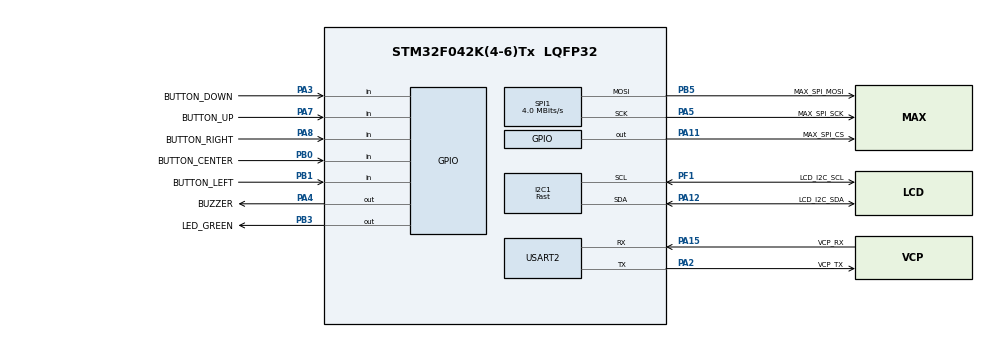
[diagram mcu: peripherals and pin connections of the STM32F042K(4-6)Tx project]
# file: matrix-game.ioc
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I2C1.I2C_Speed_Mode=I2C_Fast
I2C1.Timing=0x0010020A
Mcu.Family=STM32F0
Mcu.Name=STM32F042K(4-6)Tx
Mcu.Package=LQFP32
PA11.GPIO_Label=MAX_SPI_CS
PA11.PinState=GPIO_PIN_SET
PA11.Signal=GPIO_Output
PA12.GPIO_Label=LCD_I2C_SDA
PA12.Mode=I2C
PA12.Signal=I2C1_SDA
PA13.GPIO_Label=SWDIO
PA13.Mode=Serial_Wire
PA13.Signal=SYS_SWDIO
PA14.GPIO_Label=SWCLK
PA14.Mode=Serial_Wire
PA14.Signal=SYS_SWCLK
PA15.GPIO_Label=VCP_RX
PA15.Mode=Asynchronous
PA15.Signal=USART2_RX
PA2.GPIO_Label=VCP_TX
PA2.Mode=Asynchronous
PA2.Signal=USART2_TX
PA3.GPIO_Label=BUTTON_DOWN
PA3.GPIO_PuPd=GPIO_PULLDOWN
PA3.Signal=GPIO_Input
PA4.GPIO_Label=BUZZER
PA4.Signal=GPIO_Output
PA5.GPIO_Label=MAX_SPI_SCK
PA5.Mode=TX_Only_Simplex_Unidirect_Master
PA5.Signal=SPI1_SCK
PA7.GPIO_Label=BUTTON_UP
PA7.GPIO_PuPd=GPIO_PULLDOWN
PA7.Signal=GPIO_Input
PA8.GPIO_Label=BUTTON_RIGHT
PA8.GPIO_PuPd=GPIO_PULLDOWN
PA8.Signal=GPIO_Input
PB0.GPIO_Label=BUTTON_CENTER
PB0.GPIO_PuPd=GPIO_PULLDOWN
PB0.Signal=GPIO_Input
PB1.GPIO_Label=BUTTON_LEFT
PB1.GPIO_PuPd=GPIO_PULLDOWN
PB1.Signal=GPIO_Input
PB3.GPIO_Label=LED_GREEN
PB3.Signal=GPIO_Output
PB5.GPIO_Label=MAX_SPI_MOSI
PB5.Mode=TX_Only_Simplex_Unidirect_Master
PB5.Signal=SPI1_MOSI
PF0-OSC_IN.GPIO_Label=MCO
PF0-OSC_IN.Mode=HSE-External-Clock-Source
PF0-OSC_IN.Signal=RCC_OSC_IN
PF1-OSC_OUT.GPIO_Label=LCD_I2C_SCL
PF1-OSC_OUT.Mode=I2C
PF1-OSC_OUT.Signal=I2C1_SCL
ProjectManager.HeapSize=0x200
ProjectManager.StackSize=0x400
ProjectManager.TargetToolchain=STM32CubeIDE
SPI1.BaudRatePrescaler=SPI_BAUDRATEPRESCALER_2
SPI1.CalculateBaudRate=4.0 MBits/s
SPI1.DataSize=SPI_DATASIZE_16BIT
SPI1.Direction=SPI_DIRECTION_2LINES
SPI1.Mode=SPI_MODE_MASTER
SPI1.NSSPMode=SPI_NSS_PULSE_DISABLE
SPI1.VirtualType=VM_MASTER
USART2.VirtualMode-Asynchronous=VM_ASYNC
board=NUCLEO-F042K6

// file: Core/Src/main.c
/* USER CODE BEGIN Header */
/**
  ******************************************************************************
  * @file           : main.c
  * @brief          : Main program body
  ******************************************************************************
  * @attention
  *
  * Copyright (c) 2025 STMicroelectronics.
  * All rights reserved.
  *
  * This software is licensed under terms that can be found in the LICENSE file
  * in the root directory of this software component.
  * If no LICENSE file comes with this software, it is provided AS-IS.
  *
  ******************************************************************************
  */
/* USER CODE END Header */
#include "main.h"

/* USER CODE BEGIN Includes */
#include "app.h"

/* USER CODE END Includes */

I2C_HandleTypeDef hi2c1;

SPI_HandleTypeDef hspi1;

UART_HandleTypeDef huart2;

void SystemClock_Config(void);
static void MX_GPIO_Init(void);
static void MX_USART2_UART_Init(void);
static void MX_I2C1_Init(void);
static void MX_SPI1_Init(void);

int main(void)
{

  /* MCU Configuration--------------------------------------------------------*/

  /* Reset of all peripherals, Initializes the Flash interface and the Systick. */
  HAL_Init();

  /* Configure the system clock */
  SystemClock_Config();

  /* Initialize all configured peripherals */
  MX_GPIO_Init();
  MX_USART2_UART_Init();
  MX_I2C1_Init();
  MX_SPI1_Init();
  /* USER CODE BEGIN 2 */

  app(); // Never returns

  /* USER CODE END 2 */

  /* Infinite loop */
  while (1)
  {

  }
}

void SystemClock_Config(void)
{
  RCC_OscInitTypeDef RCC_OscInitStruct = {0};
  RCC_ClkInitTypeDef RCC_ClkInitStruct = {0};
  RCC_PeriphCLKInitTypeDef PeriphClkInit = {0};

  /** Initializes the RCC Oscillators according to the specified parameters
  * in the RCC_OscInitTypeDef structure.
  */
  RCC_OscInitStruct.OscillatorType = RCC_OSCILLATORTYPE_HSI;
  RCC_OscInitStruct.HSIState = RCC_HSI_ON;
  RCC_OscInitStruct.HSICalibrationValue = RCC_HSICALIBRATION_DEFAULT;
  RCC_OscInitStruct.PLL.PLLState = RCC_PLL_NONE;
  if (HAL_RCC_OscConfig(&RCC_OscInitStruct) != HAL_OK)
  {
    Error_Handler();
  }

  /** Initializes the CPU, AHB and APB buses clocks
  */
  RCC_ClkInitStruct.ClockType = RCC_CLOCKTYPE_HCLK|RCC_CLOCKTYPE_SYSCLK
                              |RCC_CLOCKTYPE_PCLK1;
  RCC_ClkInitStruct.SYSCLKSource = RCC_SYSCLKSOURCE_HSI;
  RCC_ClkInitStruct.AHBCLKDivider = RCC_SYSCLK_DIV1;
  RCC_ClkInitStruct.APB1CLKDivider = RCC_HCLK_DIV1;

  if (HAL_RCC_ClockConfig(&RCC_ClkInitStruct, FLASH_LATENCY_0) != HAL_OK)
  {
    Error_Handler();
  }
  PeriphClkInit.PeriphClockSelection = RCC_PERIPHCLK_I2C1;
  PeriphClkInit.I2c1ClockSelection = RCC_I2C1CLKSOURCE_HSI;
  if (HAL_RCCEx_PeriphCLKConfig(&PeriphClkInit) != HAL_OK)
  {
    Error_Handler();
  }
}

static void MX_I2C1_Init(void)
{

  hi2c1.Instance = I2C1;
  hi2c1.Init.Timing = 0x0010020A;
  hi2c1.Init.OwnAddress1 = 0;
  hi2c1.Init.AddressingMode = I2C_ADDRESSINGMODE_7BIT;
  hi2c1.Init.DualAddressMode = I2C_DUALADDRESS_DISABLE;
  hi2c1.Init.OwnAddress2 = 0;
  hi2c1.Init.OwnAddress2Masks = I2C_OA2_NOMASK;
  hi2c1.Init.GeneralCallMode = I2C_GENERALCALL_DISABLE;
  hi2c1.Init.NoStretchMode = I2C_NOSTRETCH_DISABLE;
  if (HAL_I2C_Init(&hi2c1) != HAL_OK)
  {
    Error_Handler();
  }

  /** Configure Analogue filter
  */
  if (HAL_I2CEx_ConfigAnalogFilter(&hi2c1, I2C_ANALOGFILTER_ENABLE) != HAL_OK)
  {
    Error_Handler();
  }

  /** Configure Digital filter
  */
  if (HAL_I2CEx_ConfigDigitalFilter(&hi2c1, 0) != HAL_OK)
  {
    Error_Handler();
  }

}

static void MX_SPI1_Init(void)
{

  /* SPI1 parameter configuration*/
  hspi1.Instance = SPI1;
  hspi1.Init.Mode = SPI_MODE_MASTER;
  hspi1.Init.Direction = SPI_DIRECTION_2LINES;
  hspi1.Init.DataSize = SPI_DATASIZE_16BIT;
  hspi1.Init.CLKPolarity = SPI_POLARITY_LOW;
  hspi1.Init.CLKPhase = SPI_PHASE_1EDGE;
  hspi1.Init.NSS = SPI_NSS_SOFT;
  hspi1.Init.BaudRatePrescaler = SPI_BAUDRATEPRESCALER_2;
  hspi1.Init.FirstBit = SPI_FIRSTBIT_MSB;
  hspi1.Init.TIMode = SPI_TIMODE_DISABLE;
  hspi1.Init.CRCCalculation = SPI_CRCCALCULATION_DISABLE;
  hspi1.Init.CRCPolynomial = 7;
  hspi1.Init.CRCLength = SPI_CRC_LENGTH_DATASIZE;
  hspi1.Init.NSSPMode = SPI_NSS_PULSE_DISABLE;
  if (HAL_SPI_Init(&hspi1) != HAL_OK)
  {
    Error_Handler();
  }

}

static void MX_USART2_UART_Init(void)
{

  huart2.Instance = USART2;
  huart2.Init.BaudRate = 38400;
  huart2.Init.WordLength = UART_WORDLENGTH_8B;
  huart2.Init.StopBits = UART_STOPBITS_1;
  huart2.Init.Parity = UART_PARITY_NONE;
  huart2.Init.Mode = UART_MODE_TX_RX;
  huart2.Init.HwFlowCtl = UART_HWCONTROL_NONE;
  huart2.Init.OverSampling = UART_OVERSAMPLING_16;
  huart2.Init.OneBitSampling = UART_ONE_BIT_SAMPLE_DISABLE;
  huart2.AdvancedInit.AdvFeatureInit = UART_ADVFEATURE_NO_INIT;
  if (HAL_UART_Init(&huart2) != HAL_OK)
  {
    Error_Handler();
  }

}

static void MX_GPIO_Init(void)
{
  GPIO_InitTypeDef GPIO_InitStruct = {0};

  /* GPIO Ports Clock Enable */
  __HAL_RCC_GPIOF_CLK_ENABLE();
  __HAL_RCC_GPIOA_CLK_ENABLE();
  __HAL_RCC_GPIOB_CLK_ENABLE();

  /*Configure GPIO pin Output Level */
  HAL_GPIO_WritePin(GPIOA, BUZZER_Pin|MAX_SPI_CS_Pin, GPIO_PIN_RESET);

  /*Configure GPIO pin Output Level */
  HAL_GPIO_WritePin(LED_GREEN_GPIO_Port, LED_GREEN_Pin, GPIO_PIN_RESET);

  /*Configure GPIO pins : BUTTON_DOWN_Pin BUTTON_UP_Pin BUTTON_RIGHT_Pin */
  GPIO_InitStruct.Pin = BUTTON_DOWN_Pin|BUTTON_UP_Pin|BUTTON_RIGHT_Pin;
  GPIO_InitStruct.Mode = GPIO_MODE_INPUT;
  GPIO_InitStruct.Pull = GPIO_PULLDOWN;
  HAL_GPIO_Init(GPIOA, &GPIO_InitStruct);

  /*Configure GPIO pins : BUZZER_Pin MAX_SPI_CS_Pin */
  GPIO_InitStruct.Pin = BUZZER_Pin|MAX_SPI_CS_Pin;
  GPIO_InitStruct.Mode = GPIO_MODE_OUTPUT_PP;
  GPIO_InitStruct.Pull = GPIO_NOPULL;
  GPIO_InitStruct.Speed = GPIO_SPEED_FREQ_LOW;
  HAL_GPIO_Init(GPIOA, &GPIO_InitStruct);

  /*Configure GPIO pins : BUTTON_CENTER_Pin BUTTON_LEFT_Pin */
  GPIO_InitStruct.Pin = BUTTON_CENTER_Pin|BUTTON_LEFT_Pin;
  GPIO_InitStruct.Mode = GPIO_MODE_INPUT;
  GPIO_InitStruct.Pull = GPIO_PULLDOWN;
  HAL_GPIO_Init(GPIOB, &GPIO_InitStruct);

  /*Configure GPIO pin : LED_GREEN_Pin */
  GPIO_InitStruct.Pin = LED_GREEN_Pin;
  GPIO_InitStruct.Mode = GPIO_MODE_OUTPUT_PP;
  GPIO_InitStruct.Pull = GPIO_NOPULL;
  GPIO_InitStruct.Speed = GPIO_SPEED_FREQ_LOW;
  HAL_GPIO_Init(LED_GREEN_GPIO_Port, &GPIO_InitStruct);

}

void Error_Handler(void)
{
  __disable_irq();
  while (1)
  {
  }
}
